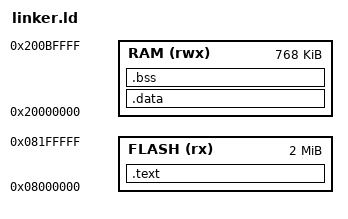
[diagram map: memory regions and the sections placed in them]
ENTRY(Reset_Handler)

MEMORY
{
    FLASH (rx) : ORIGIN = 0x08000000, LENGTH = 2048K
    RAM (rwx)  : ORIGIN = 0x20000000, LENGTH = 768K
}

SECTIONS
{
    .text :
    {
        *(.isr_vector)
        *(.text)
        *(.rodata)
    } > FLASH

    .data :
    {
        *(.data)
    } > RAM

    .bss :
    {
        *(.bss)
    } > RAM
}
